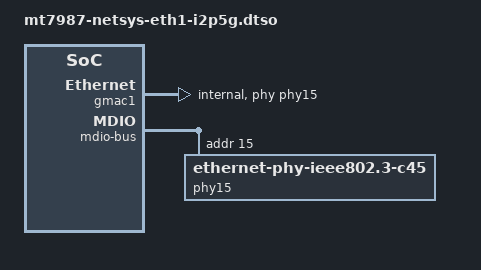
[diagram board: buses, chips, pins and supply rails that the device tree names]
// SPDX-License-Identifier: (GPL-2.0 OR MIT)

/dts-v1/;
/plugin/;

/ {
	fragment@0 {
		target-path = "/soc_netsys/ethernet@15100000";
		__overlay__ {
			gmac1: mac@1 {
				compatible = "mediatek,eth-mac";
				reg = <1>;
				phy-mode = "internal";
				phy-handle = <&phy15>;
			};
		};
	};

	fragment@1 {
		target-path = "/soc_netsys/ethernet@15100000/mdio-bus";
		__overlay__ {
			/* built-in 2.5G Ethernet PHY */
			phy15: phy@15 {
				pinctrl-names = "i2p5gbe-led";
				pinctrl-0 = <&i2p5gbe_led0_pins>;
				compatible = "ethernet-phy-ieee802.3-c45";
				reg = <15>;
				phy-mode = "internal";
			};
		};
	};
};

